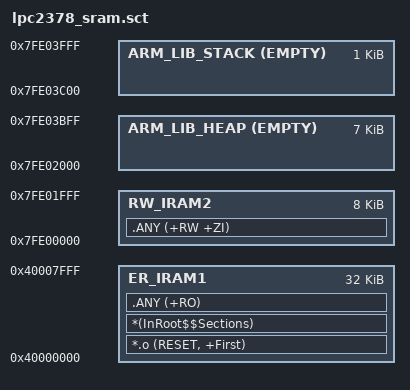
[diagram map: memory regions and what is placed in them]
;*****************************************************************
;* LPC2378 linker scatter file (running code from internal SRAM) *
;*****************************************************************

LR_IRAM1 0x40000000 0x8000
{
   ER_IRAM1 0x40000000 0x8000
   {
      *.o (RESET, +First)
      *(InRoot$$Sections)
      .ANY (+RO)
   }
   
   RW_IRAM2 0x7FE00000 0x2000
   { 
      .ANY (+RW +ZI)
   }
   
   ARM_LIB_STACK 0x7FE04000 EMPTY -0x400
   {
   }
   
   ARM_LIB_HEAP 0x7FE02000 EMPTY 0x1C00
   {
   }
}
